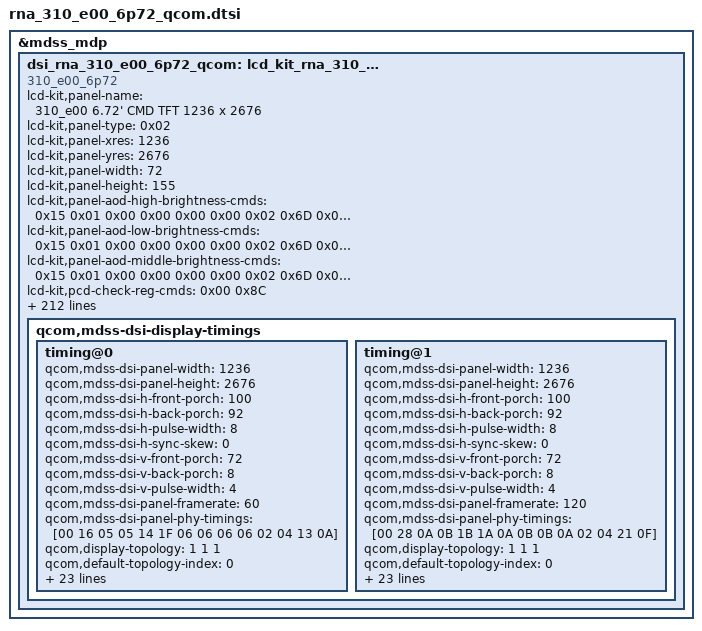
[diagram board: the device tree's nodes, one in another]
/* Copyright (c) 2013, The Linux Foundation. All rights reserved.
 *
 * This program is free software; you can redistribute it and/or modify
 * it under the terms of the GNU General Public License version 2 and
 * only version 2 as published by the Free Software Foundation.
 *
 * This program is distributed in the hope that it will be useful,
 * but WITHOUT ANY WARRANTY; without even the implied warranty of
 * MERCHANTABILITY or FITNESS FOR A PARTICULAR PURPOSE.  See the
 * GNU General Public License for more details.
 */

/*-------------------------------------------------------------------------
 * This file is autogenerated file using gcdb parser. Please do not edit it.
 * Update input XML file to add a new entry or update variable in this file
 * VERSION = 1.1
 *-----------------------------------------------------------------------*/
&mdss_mdp {
	dsi_rna_310_e00_6p72_qcom: lcd_kit_rna_310_e00_6p72_qcom {
		compatible = "310_e00_6p72";
		lcd-kit,panel-name = "310_e00 6.72' CMD TFT 1236 x 2676";
		lcd-kit,panel-type = <0x02>;
		lcd-kit,panel-xres = <1236>;
		lcd-kit,panel-yres = <2676>;
		lcd-kit,panel-width = <72>;
		lcd-kit,panel-height = <155>;
		lcd-kit,panel-aod-high-brightness-cmds = <0x15 0x01 0x00 0x00 0x00 0x00 0x02 0x6D 0x00
		0x05 0x01 0x00 0x00 0x00 0x00 0x01 0x13>;
		lcd-kit,panel-aod-low-brightness-cmds = <0x15 0x01 0x00 0x00 0x00 0x00 0x02 0x6D 0x02
		0x05 0x01 0x00 0x00 0x00 0x00 0x01 0x13>;
		lcd-kit,panel-aod-middle-brightness-cmds = <0x15 0x01 0x00 0x00 0x00 0x00 0x02 0x6D 0x01
		0x05 0x01 0x00 0x00 0x00 0x00 0x01 0x13>;
		lcd-kit,pcd-check-reg-cmds = <0x00 0x8C>;
		lcd-kit,check-reg-on-cmds = <0x06 0x01 0x00 0x00 0x0a 0x00 0x01 0x0a>;
		lcd-kit,check-reg-on-value = <0x9c>;
		lcd-kit,check-aod-reg-on-cmds = <0x06 0x01 0x00 0x00 0x0a 0x00 0x01 0x0a>;
		lcd-kit,check-aod-reg-on-value = <0xdc>;
		lcd-kit,check-reg-off-cmds = <0x06 0x01 0x00 0x00 0x0a 0x00 0x01 0x0a>;
		lcd-kit,check-reg-off-value = <0x08>;
		lcd-kit,check-reg-on-cmds-state = "dsi_lp_mode";
		lcd-kit,check-aod-reg-on-cmds-state = "dsi_lp_mode";
		lcd-kit,check-reg-off-cmds-state = "dsi_lp_mode";
		lcd-kit,pcd-check-reg-value = <0x00 0x8C>;
		lcd-kit,pcd-errflag-check-support = <0>;
		lcd-kit,checksum-enable-cmds = <0x39 0x01 0x00 0x00 0x14 0x00 0x05 0xFF 0xAA 0x55 0xA5 0x80
		0x15 0x01 0x00 0x00 0x0a 0x00 0x02 0xF2 0x03>;
		lcd-kit,checksum-enable-cmds-state = "dsi_lp_mode";
		lcd-kit,checksum-disable-cmds = <0x39 0x01 0x00 0x00 0x14 0x00 0x05 0xFF 0xAA 0x55 0xA5 0x80
		0x15 0x01 0x00 0x00 0x0a 0x00 0x02 0xF2 0x00>;
		lcd-kit,checksum-disable-cmds-state = "dsi_lp_mode";
		lcd-kit,checksum-cmds = <0x39 0x01 0x00 0x00 0x14 0x00 0x05 0xFF 0xAA 0x55 0xA5 0x80
		0x15 0x01 0x00 0x00 0x0a 0x00 0x02 0x6F 0x01
		0x14 0x01 0x00 0x00 0x0a 0x00 0x08 0xF2 0x00 0x00 0x00 0x00 0x00 0x00 0x00>;
		lcd-kit,checksum-cmds-state = "dsi_lp_mode";
		lcd-kit,checksum-value = <0x06 0xf2 0x7d 0x83 0x91 0xe7 0x4c 0x2a
		0xba 0xeb 0x79 0x7c 0xe4 0xb4 0xcb 0x62
		0x97 0x89 0xd0 0x7a 0xc4 0xee 0xf7 0x69>;
		lcd-kit,hor-line-cmds = <0x39 0x01 0x00 0x00 0x0a 0x00 0x06 0xF0 0x55 0xAA 0x52 0x08 0x01
		0x15 0x01 0x00 0x00 0x0a 0x00 0x02 0xB3 0x23
		0x15 0x01 0x00 0x00 0x0a 0x00 0x02 0xB4 0x23
		0x15 0x01 0x00 0x00 0x0a 0x00 0x02 0xB0 0x0B
		0x15 0x01 0x00 0x00 0x0a 0x00 0x02 0xB1 0x08
		0x39 0x01 0x00 0x00 0x0a 0x00 0x09 0xB7 0x46 0x46 0x46 0x46 0x46 0x46 0x46 0x46
		0x39 0x01 0x00 0x00 0x0a 0x00 0x08 0xB8 0x5F 0x5F 0x5F 0x5F 0x5F 0x5F 0x5F
		0x15 0x01 0x00 0x00 0x0a 0x00 0x02 0x2F 0x03
		0x39 0x01 0x00 0x00 0x0a 0x00 0x06 0xF0 0x55 0xAA 0x52 0x08 0x00
		0x39 0x01 0x00 0x00 0x0a 0x00 0x03 0xB2 0x11 0x00
		0x39 0x01 0x00 0x00 0x0a 0x00 0x03 0x51 0x00 0x00
		0x39 0x01 0x00 0x00 0x0a 0x00 0x06 0xF0 0x55 0xAA 0x52 0x08 0x06
		0x15 0x01 0x00 0x00 0x0a 0x00 0x02 0x6F 0x02
		0x39 0x01 0x00 0x00 0x0a 0x00 0x03 0xB1 0x31 0x31
		0x15 0x01 0x00 0x00 0x0a 0x00 0x02 0x6F 0x02
		0x39 0x01 0x00 0x00 0x0a 0x00 0x03 0xB7 0x31 0x31>;
		lcd-kit,hor-line-cmds-state = "dsi_lp_mode";
		lcd-kit,pcd-read-cmds = <0x39 0x01 0x00 0x00 0x00 0x00 0x03 0xF0 0xAA 0x12
		0x15 0x01 0x00 0x00 0x00 0x00 0x02 0xD0 0x8C
		0x15 0x01 0x00 0x00 0x00 0x00 0x02 0x65 0x03
		0x06 0x01 0x00 0x00 0x00 0x00 0x01 0xD0
		0x15 0x01 0x00 0x00 0x00 0x00 0x02 0xD0 0x0C>;
		lcd-kit,pcd-read-cmds-state  = "dsi_lp_mode";
		lcd-kit,vtc-line-cmds = <0x39 0x01 0x00 0x00 0x0a 0x00 0x06 0xF0 0x55 0xAA 0x52 0x08 0x00
		0x15 0x01 0x00 0x00 0x0a 0x00 0x02 0x6F 0x06
		0x15 0x01 0x00 0x00 0x0a 0x00 0x02 0xB5 0x4E
		0x39 0x01 0x00 0x00 0x0a 0x00 0x06 0xF0 0x55 0xAA 0x52 0x08 0x01
		0x15 0x01 0x00 0x00 0x0a 0x00 0x02 0xCF 0x00
		0x39 0x01 0x00 0x00 0x0a 0x00 0x03 0xB5 0x00 0xF0
		0x39 0x01 0x00 0x00 0x0a 0x00 0x03 0xB6 0x01 0x60
		0x39 0x01 0x00 0x00 0x0a 0x00 0x06 0xF0 0x55 0xAA 0x52 0x08 0x00
		0x15 0x01 0x00 0x00 0x0a 0x00 0x02 0xC5 0x01
		0x39 0x01 0x00 0x00 0x0a 0x00 0x06 0xF0 0x55 0xAA 0x52 0x08 0x05
		0x15 0x01 0x00 0x00 0x0a 0x00 0x02 0xEC 0x01
		0x39 0x01 0x00 0x00 0x0a 0x00 0x03 0x51 0x0F 0xFF
		0x15 0x01 0x00 0x00 0x0a 0x00 0x02 0x53 0x20
		0x39 0x01 0x00 0x00 0x0a 0x00 0x06 0xF0 0x55 0xAA 0x52 0x08 0x01
		0x15 0x01 0x00 0x00 0x0a 0x00 0x02 0xB3 0x23
		0x15 0x01 0x00 0x00 0x0a 0x00 0x02 0xB4 0x23
		0x15 0x01 0x00 0x00 0x0a 0x00 0x02 0xB0 0x0B
		0x15 0x01 0x00 0x00 0x0a 0x00 0x02 0xB1 0x08
		0x39 0x01 0x00 0x00 0x0a 0x00 0x09 0xB7 0x46 0x46 0x46 0x46 0x46 0x46 0x46 0x46
		0x39 0x01 0x00 0x00 0x0a 0x00 0x08 0xB8 0x5F 0x5F 0x5F 0x5F 0x5F 0x5F 0x5F
		0x39 0x01 0x00 0x00 0x0a 0x00 0x06 0xF0 0x55 0xAA 0x52 0x08 0x07
		0x39 0x01 0x00 0x00 0x0a 0x00 0x07 0xB1 0x10 0x60 0x40 0x00 0x20 0x50
		0x05 0x01 0x00 0x00 0x46 0x01 0x01 0x11
		0x05 0x01 0x00 0x00 0x0a 0x01 0x01 0x28>;
		lcd-kit,vtc-line-cmds-state  = "dsi_lp_mode";
		lcd-kit,ddic-lv-det-enter1-cmds = <0x39 0x01 0x00 0x00 0x0a 0x00 0x06 0xF0 0x55 0xAA 0x52 0x08 0x01
		0x39 0x01 0x00 0x00 0x14 0x00 0x05 0xC7 0x68 0x34 0x30 0x0F>;
		lcd-kit,ddic-lv-det-enter1-cmds-state  = "dsi_lp_mode";
		lcd-kit,ddic-lv-det-enter2-cmds = <0x39 0x01 0x00 0x00 0x0a 0x00 0x06 0xF0 0x55 0xAA 0x52 0x08 0x01
		0x39 0x01 0x00 0x00 0x14 0x00 0x05 0xC7 0x68 0x34 0x30 0x0F>;
		lcd-kit,ddic-lv-det-enter2-cmds-state  = "dsi_lp_mode";
		lcd-kit,ddic-lv-det-enter3-cmds = <0x39 0x01 0x00 0x00 0x0a 0x00 0x06 0xF0 0x55 0xAA 0x52 0x08 0x01
		0x39 0x01 0x00 0x00 0x14 0x00 0x05 0xC7 0x68 0x34 0x30 0x0F>;
		lcd-kit,ddic-lv-det-enter3-cmds-state  = "dsi_lp_mode";
		lcd-kit,ddic-lv-det-enter4-cmds = <0x39 0x01 0x00 0x00 0x0a 0x00 0x06 0xF0 0x55 0xAA 0x52 0x08 0x01
		0x39 0x01 0x00 0x00 0x14 0x00 0x05 0xC7 0x68 0x34 0x30 0x0F>;
		lcd-kit,ddic-lv-det-enter4-cmds-state  = "dsi_lp_mode";
		lcd-kit,ddic-lv-det-rd1-cmds = <0x06 0x01 0x00 0x00 0x0a 0x00 0x01 0x0a>;
		lcd-kit,ddic-lv-det-rd1-cmds-state  = "dsi_lp_mode";
		lcd-kit,ddic-lv-det-rd2-cmds = <0x06 0x01 0x00 0x00 0x0a 0x00 0x01 0x0a>;
		lcd-kit,ddic-lv-det-rd2-cmds-state  = "dsi_lp_mode";
		lcd-kit,ddic-lv-det-rd3-cmds = <0x06 0x01 0x00 0x00 0x0a 0x00 0x01 0x0a>;
		lcd-kit,ddic-lv-det-rd3-cmds-state  = "dsi_lp_mode";
		lcd-kit,ddic-lv-det-rd4-cmds = <0x06 0x01 0x00 0x00 0x0a 0x00 0x01 0x0a>;
		lcd-kit,ddic-lv-det-rd4-cmds-state  = "dsi_lp_mode";
		lcd-kit,ddic-lv-det-value1 = <0x9c>;
		lcd-kit,ddic-lv-det-value2 = <0x9c>;
		lcd-kit,ddic-lv-det-value3 = <0x9c>;
		lcd-kit,ddic-lv-det-value4 = <0x9c>;
		lcd-kit,ap-aod-support = <1>;
		lcd-kit,mask-delay-time-before-fp = <16667>;
		lcd-kit,mask-delay-time-after-fp = <16667>;
		lcd-kit,left-time-to-te-us = <28667>;
		lcd-kit,right-time-to-te-us = <29667>;
		lcd-kit,te-interval-time-us = <16667>;
		lcd-kit,oneside-mode-support = <0>;
		lcd-kit,color-aod-detect-support = <0>;
		lcd-kit,elvdd-detect-support = <0>;
		lcd-kit,elvdd-detect-type = <2>;
		lcd-kit,elvdd-detect-value = <1>;
		lcd-kit,elvdd-delay = <50>;
		lcd-kit,elvdd-detect-gpio = <104>;
		lcd-kit,check-reg-on-support = <0>;
		lcd-kit,check-reg-on-support-dsm-report = <0>;
		lcd-kit,check-aod-reg-on-support = <0>;
		lcd-kit,check-aod-reg-on-support-dsm-report = <0>;
		lcd-kit,check-reg-off-support = <0>;
		lcd-kit,check-reg-off-support-dsm-report = <0>;
		lcd-kit,checksum-support = <0>;
		lcd-kit,pcd-cmds-support = <0>;
		lcd-kit,pcd-check-reg-value-compare-mode = <3>;
		lcd-kit,vtc-line-support = <0>;
		lcd-kit,ddic-lv-det-support = <0>;
		lcd-kit,hor-line-support = <0>;
		lcd-kit,hor-line-duration = <600>;
		qcom,mdss-dsi-panel-type = "dsi_cmd_mode";
		qcom,mdss-pan-physical-width-dimension = <72>;
		qcom,mdss-pan-physical-height-dimension = <155>;
		qcom,dsi-ctrl-num = <0>;
		qcom,dsi-phy-num = <0>;
		qcom,panel-supply-entries = <&dsi_panel_pwr_supply>;
		qcom,mdss-dsi-virtual-channel-id = <0>;
		qcom,mdss-dsi-h-sync-pulse = <0>;
		qcom,mdss-dsi-bllp-eof-power-mode;
		qcom,mdss-dsi-bllp-power-mode;
		qcom,mdss-dsi-dma-schedule-line = <1>;
		qcom,mdss-dsi-bpp = <24>;
		qcom,mdss-dsi-color-order = "rgb_swap_rgb";
		qcom,mdss-dsi-underflow-color = <0xff>;
		qcom,mdss-dsi-border-color = <0>;
		qcom,mdss-dsi-traffic-mode = "burst_mode";
		qcom,mdss-dsi-lane-map = "lane_map_0123";
		qcom,mdss-dsi-lane-0-state;
		qcom,mdss-dsi-lane-1-state;
		qcom,mdss-dsi-lane-2-state;
		qcom,mdss-dsi-lane-3-state;
		qcom,mdss-dsi-mdp-trigger = "none";
		qcom,mdss-dsi-dma-trigger = "trigger_sw";
		qcom,mdss-dsi-te-pin-select = <1>;
		qcom,mdss-dsi-wr-mem-start = <0x2c>;
		qcom,mdss-dsi-wr-mem-continue = <0x3c>;
		qcom,mdss-dsi-te-dcs-command = <1>;
		qcom,mdss-dsi-te-check-enable;
		qcom,mdss-dsi-te-using-te-pin;
		qcom,dsi-panel-gpio-address = <0x0F100000 0x1000>;
		qcom,dsi-panel-gpio-pins = <12 44 80>;
		qcom,dsi-panel-gpio-names = "reg-gpio", "reset-gpio", "platform-te-gpio";
		qcom,mdss-dsi-t-clk-post = <0>;
		qcom,mdss-dsi-t-clk-pre = <0>;
		qcom,dsi-select-clocks = "mux_byte_clk0", "mux_pixel_clk0";
		qcom,mdss-dsi-stream = <0>;
		qcom,mdss-dsi-lp11-init;
		qcom,sublinks-count = <2>;
		qcom,lanes-per-sublink = <2>;
		qcom,mdss-dsi-panel-hdr-color-primaries = <14500 15500 32000 17000 15500 30000 8000 3000>;
		qcom,mdss-dsi-panel-peak-brightness = <4200000>;
		qcom,mdss-dsi-panel-blackness-level = <3230>;
		qcom,dynamic-mode-switch-enabled;
		qcom,dynamic-mode-switch-type = "dynamic-resolution-switch-immediate";
		qcom,mdss-dsi-bl-pmic-control-type = "bl_ctrl_dcs";
		qcom,mdss-dsi-bl-min-level = <1>;
		qcom,mdss-dsi-bl-max-level = <10000>;
		qcom,esd-check-enabled;
		qcom,mdss-dsi-panel-status-command = [06 01 00 00 00 00 02 68 00
			06 01 00 00 00 00 01 0A
			39 01 00 00 00 00 03 FF 5A 80
			15 01 00 00 00 00 02 65 37
			06 01 00 00 00 00 03 F5 00 00
			39 01 00 00 00 00 03 F0 AA 10
			06 01 00 00 00 00 02 ed 00];
		qcom,mdss-dsi-panel-status-command-state = "dsi_lp_mode";
		qcom,mdss-dsi-panel-status-check-mode = "reg_read";
		qcom,mdss-dsi-panel-status-read-length = <2 1 0 0 3 0 2>;
		qcom,mdss-dsi-panel-status-value = <0x00 0x00>,<0x9C>,<0x00 0x00 0x00>,<0x00 0x30>;
		lcd-kit,power-on-stage = <2 1 2
				1 1 1
				9 1 15
				5 1 5
				5 0 1
				5 1 15
				7 1 0
				6 1 0
				8 1 0>;
		lcd-kit,lp-on-stage = <0 0 0>;
		lcd-kit,lp-off-stage = <0 0 0>;
		lcd-kit,power-off-stage = <7 0 0
				6 0 0
				8 0 0
				5 0 1
				9 0 1
				1 0 2
				2 0 1>;
		lcd-kit,only-power-off-stage = <0 0 0>;
		lcd-kit,pt-support = <1>;
		lcd-kit,panel-on-always-reset = <0>;
		lcd-kit,lcd-vci = <1 13 3000000 3000000 3000000 10000 80>;
		lcd-kit,lcd-iovcc = <1 12 1800000 1800000 1800000 60700 80>;
		lcd-kit,lcd-vdd = <1 16 1200000 1200000 1200000 30000 80>;
		lcd-kit,lcd-reset = <2 44 0>;
		lcd-kit,lcd-vci-name = "vdd";
		lcd-kit,lcd-iovcc-name = "vddio";
		lcd-kit,lcd-vdd-name = "ddic";
		lcd-kit,project-id-support = <0>;
		lcd-kit,default-project-id = "B2359S2920";
		lcd-kit,sn-code-support = <1>;
		lcd-kit,oem-info-support = <1>;
		lcd-kit,oem-barcode-2d-support = <1>;
		lcd-kit,oem-barcode-2d-num-offset = <0>;
		lcd-kit,barcode-2d-cmds = <0x39 0x01 0x00 0x00 0x0a 0x00 0x03 0xF0 0xAA 0x10
                  0x14 0x01 0x00 0x00 0x0a 0x00 0x17 0xC8 0x00 0x00 0x00 0x00 0x00 0x00 0x00 0x00 0x00 0x00 0x00 0x00 0x00 0x00 0x00 0x00 0x00 0x00 0x00 0x00 0x00 0x00>;
		lcd-kit,barcode-2d-cmds-state = "dsi_lp_mode";
		lcd-kit,panel-getblmaxnit-type = <0>;
		lcd-kit,panel-blmaxnit-min-value = <400>;
		lcd-kit,inversion-support = <0>;
		lcd-kit,panel-gpio-offset = <336>;
		lcd-kit,finger-unlock-state-support = <0>;
		lcd-kit,finger-handle-esd-support = <1>;
		lcd-kit,panel-bl-max-nit = <450>;
		lcd-kit,panel-bl-min = <3>;
		lcd-kit,panel-bl-max = <10000>;
		lcd-kit,panel-bl-def = <128>;
		lcd-kit,check-reg-support = <0>;
		lcd-kit,thp-proximity-support = <0>;
		lcd-kit,proximity-reset-delay-min = <65>;
		lcd-kit,backlight-cmds = <0x39 0x01 0x00 0x00 0x00 0x00 0x03 0x51 0x00 0x00>;
		lcd-kit,backlight-cmds-state = "dsi_lp_mode";
		lcd-kit,backlight-order = <0>;
		lcd-kit,backlight-need-sync = <0>;
		lcd-kit,fps-support = <1>;
		lcd-kit,default-fps = <60>;
		lcd-kit,panel-support-fps-list = <60 120>;
		qcom,mdss-dsi-display-timings {
			timing@0 {
				qcom,mdss-dsi-panel-width = <1236>;
				qcom,mdss-dsi-panel-height = <2676>;
				qcom,mdss-dsi-h-front-porch = <100>;
				qcom,mdss-dsi-h-back-porch = <92>;
				qcom,mdss-dsi-h-pulse-width = <8>;
				qcom,mdss-dsi-h-sync-skew = <0>;
				qcom,mdss-dsi-v-front-porch = <72>;
				qcom,mdss-dsi-v-back-porch = <8>;
				qcom,mdss-dsi-v-pulse-width = <4>;
				qcom,mdss-dsi-panel-framerate = <60>;
				qcom,mdss-dsi-panel-phy-timings= [00 16 05 05 14 1F 06
			06 06 06 02 04 13 0A];
				qcom,display-topology  = <1 1 1>;
				qcom,default-topology-index  = <0>;
				qcom,mdss-dsi-on-command = [39 01 00 00 0a 00 03 f0 aa 12
		39 01 00 00 00 00 05 C7 2F 43 32 44
		39 01 00 00 00 00 03 F0 AA 10
		15 01 00 00 00 00 02 65 16
		39 01 00 00 00 00 03 EB 00 00
		39 01 00 00 00 00 03 f0 aa 14
		39 01 00 00 00 00 03 b2 03 33
		39 01 00 00 00 00 0d b4 05 3f 00 00 05 3f 00 00 05 3f 00 00
		39 01 00 00 00 00 0a b5 00 17 17 17 17 17 17 06 01
		39 01 00 00 00 00 07 b9 00 00 08 17 17 17
		39 01 00 00 00 00 0c bc 10 00 00 08 11 17 4F 17 4F 17 4F
		39 01 00 00 00 00 0c be 10 10 00 08 22 17 34 17 34 17 34
		39 01 00 00 00 00 0a B6 00 00 00 00 00 00 00 16 15
		39 01 00 00 00 00 0c BD 10 00 00 10 10 09 39 09 39 09 39
		15 01 00 00 00 00 02 35 00
		15 01 00 00 00 00 02 53 20
		15 01 00 00 00 00 02 6c 02
		15 01 00 00 00 00 02 6f 02
		15 01 00 00 00 00 02 03 01
		39 01 00 00 0a 00 5f 70 11 00 00 80 30 80 0a 74 04 d4 00 0c 04 d4 04 d4 02 00 03 6a 00 20 01 8e 00 11 00 0c 08 bb 03 b4 18 00 10 f0 03 0c 20 00 06 0b 0b 33 0e 1c 2a 38 46 54 62 69 70 77 79 7b 7d 7e 01 02 01 00 09 40 09 be 19 fc 19 fa 19 f8 1a 38 1a 78 1a b6 2a b6 2a f4 2a f4 4b 34 63 74 00 00 00 00 00 00
		39 01 00 00 00 00 03 FF 5A 81
		15 01 00 00 00 00 02 65 05
		15 01 00 00 00 00 02 F3 0F
		15 01 00 00 00 00 02 65 01
		15 01 00 00 00 00 02 F4 9A
		39 01 00 00 00 00 03 FF 5A 80
		15 01 00 00 00 00 02 65 11
		39 01 00 00 00 00 03 FA 02 0E
		15 01 00 00 00 00 02 59 09
		39 01 00 00 00 00 03 F0 AA 10
		15 01 00 00 00 00 02 B3 C7
		39 01 00 00 00 00 03 F0 AA 00
		39 01 00 00 00 00 03 FF 5A 00
		05 01 00 00 32 00 01 11
		05 01 00 00 32 00 01 29];
				qcom,mdss-dsi-on-command-state = "dsi_lp_mode";
				qcom,mdss-dsi-off-command = [05 01 00 00 78 00 01 28
		05 01 00 00 0a 00 01 10];
				qcom,mdss-dsi-off-command-state = "dsi_lp_mode";
				qcom,compression-mode = "dsc";
				qcom,mdss-dsc-slice-height = <12>;
				qcom,mdss-dsc-slice-width = <1236>;
				qcom,mdss-dsc-slice-per-pkt = <1>;
				qcom,mdss-dsc-bit-per-component = <8>;
				qcom,mdss-dsc-bit-per-pixel = <8>;
				qcom,mdss-dsc-block-prediction-enable;
				qcom,mdss-dsi-timing-switch-command = [15 01 00 00 14 00 02 6C 02];
				qcom,mdss-dsi-timing-switch-command-state = "dsi_lp_mode";
				qcom,mdss-dsi-lp1-command = [05 01 00 00 00 00 01 22
		05 01 00 00 00 00 01 39
		39 01 00 00 00 00 03 F0 AA 10
		15 01 00 00 00 00 02 B3 C6];
				qcom,mdss-dsi-lp1-command-state = "dsi_lp_mode";
				qcom,mdss-dsi-nolp-command = [05 01 00 00 00 00 01 38
		39 01 00 00 00 00 03 F0 AA 10
		15 01 00 00 00 00 02 B3 C7
		05 01 00 00 00 00 01 13];
				qcom,mdss-dsi-nolp-command-state = "dsi_lp_mode";
			};
			timing@1 {
				qcom,mdss-dsi-panel-width = <1236>;
				qcom,mdss-dsi-panel-height = <2676>;
				qcom,mdss-dsi-h-front-porch = <100>;
				qcom,mdss-dsi-h-back-porch = <92>;
				qcom,mdss-dsi-h-pulse-width = <8>;
				qcom,mdss-dsi-h-sync-skew = <0>;
				qcom,mdss-dsi-v-front-porch = <72>;
				qcom,mdss-dsi-v-back-porch = <8>;
				qcom,mdss-dsi-v-pulse-width = <4>;
				qcom,mdss-dsi-panel-framerate = <120>;
				qcom,mdss-dsi-panel-phy-timings= [00 28 0A 0B 1B 1A 0A
			0B 0B 0A 02 04 21 0F];
				qcom,display-topology  = <1 1 1>;
				qcom,default-topology-index  = <0>;
				qcom,mdss-dsi-on-command = [39 01 00 00 0a 00 03 f0 aa 12
		39 01 00 00 00 00 05 C7 2F 43 32 44
		39 01 00 00 00 00 03 F0 AA 10
		15 01 00 00 00 00 02 65 16
		39 01 00 00 00 00 03 EB 00 00
		39 01 00 00 00 00 03 f0 aa 14
		39 01 00 00 00 00 03 b2 03 33
		39 01 00 00 00 00 0d b4 05 3f 00 00 05 3f 00 00 05 3f 00 00
		39 01 00 00 00 00 0a b5 00 17 17 17 17 17 17 06 01
		39 01 00 00 00 00 07 b9 00 00 08 17 17 17
		39 01 00 00 00 00 0c bc 10 00 00 08 11 17 4F 17 4F 17 4F
		39 01 00 00 00 00 0c be 10 10 00 08 22 17 34 17 34 17 34
		39 01 00 00 00 00 0a B6 00 00 00 00 00 00 00 16 15
		39 01 00 00 00 00 0c BD 10 00 00 10 10 09 39 09 39 09 39
		15 01 00 00 00 00 02 35 00
		15 01 00 00 00 00 02 53 20
		15 01 00 00 00 00 02 6c 00
		15 01 00 00 00 00 02 6f 02
		15 01 00 00 00 00 02 03 01
		39 01 00 00 0a 00 5f 70 11 00 00 80 30 80 0a 74 04 d4 00 0c 04 d4 04 d4 02 00 03 6a 00 20 01 8e 00 11 00 0c 08 bb 03 b4 18 00 10 f0 03 0c 20 00 06 0b 0b 33 0e 1c 2a 38 46 54 62 69 70 77 79 7b 7d 7e 01 02 01 00 09 40 09 be 19 fc 19 fa 19 f8 1a 38 1a 78 1a b6 2a b6 2a f4 2a f4 4b 34 63 74 00 00 00 00 00 00
		39 01 00 00 00 00 03 FF 5A 81
		15 01 00 00 00 00 02 65 05
		15 01 00 00 00 00 02 F3 0F
		15 01 00 00 00 00 02 65 01
		15 01 00 00 00 00 02 F4 9A
		39 01 00 00 00 00 03 FF 5A 80
		15 01 00 00 00 00 02 65 11
		39 01 00 00 00 00 03 FA 02 0E
		15 01 00 00 00 00 02 59 09
		39 01 00 00 00 00 03 F0 AA 10
		15 01 00 00 00 00 02 B3 C7
		39 01 00 00 00 00 03 F0 AA 00
		39 01 00 00 00 00 03 FF 5A 00
		05 01 00 00 32 00 01 11
		05 01 00 00 32 00 01 29];
				qcom,mdss-dsi-on-command-state = "dsi_lp_mode";
				qcom,mdss-dsi-off-command = [05 01 00 00 78 00 01 28
		05 01 00 00 0a 00 01 10];
				qcom,mdss-dsi-off-command-state = "dsi_lp_mode";
				qcom,compression-mode = "dsc";
				qcom,mdss-dsc-slice-height = <12>;
				qcom,mdss-dsc-slice-width = <1236>;
				qcom,mdss-dsc-slice-per-pkt = <1>;
				qcom,mdss-dsc-bit-per-component = <8>;
				qcom,mdss-dsc-bit-per-pixel = <8>;
				qcom,mdss-dsc-block-prediction-enable;
				qcom,mdss-dsi-timing-switch-command = [15 01 00 00 00 00 02 6C 00];
				qcom,mdss-dsi-timing-switch-command-state = "dsi_lp_mode";
				qcom,mdss-dsi-lp1-command = [05 01 00 00 00 00 01 22
		05 01 00 00 00 00 01 39
		39 01 00 00 00 00 03 F0 AA 10
		15 01 00 00 00 00 02 B3 C6];
				qcom,mdss-dsi-lp1-command-state = "dsi_lp_mode";
				qcom,mdss-dsi-nolp-command = [05 01 00 00 00 00 01 38
		39 01 00 00 00 00 03 F0 AA 10
		15 01 00 00 00 00 02 B3 C7
		05 01 00 00 00 00 01 13];
				qcom,mdss-dsi-nolp-command-state = "dsi_lp_mode";
			};
		};
    };
};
